# cyt2cl register map
Vendor: Cypress Semiconductor; Series: cyt2cl; File version: 1.0
CPU: CM4 r0p1, little endian, MPU, FPU, VTOR, 3 interrupt priority bits
Registers are 32-bit, read-write, reset 0x0 unless marked. A register's access mark holds for its fields unless they carry their own. Offsets are from the block's base; [hi:lo] are bit positions; lines under a group give offsets from that group; {n}, {i} and the like mark numbered series; 'fields as' and 'values as' point back to an identical list.

## GPIO — GPIO port control/configuration
Base 0x40310000
{0x0+0x80*i} PRT[{i}] (i=0..19) group — GPIO port registers
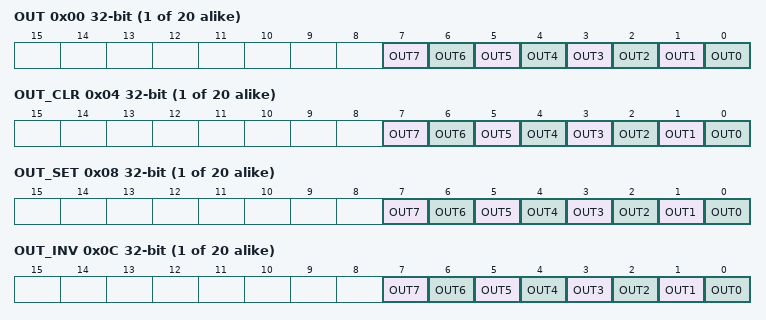
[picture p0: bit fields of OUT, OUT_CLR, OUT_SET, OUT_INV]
  0x00 OUT — Port output data register
    [n] OUT{n} (n=1..7) — IO output data for pin {n}
    [0] OUT0 — IO output data for pin 0 '0': Output state set to '0' '1': Output state set to '1'
  0x04 OUT_CLR — Port output data clear register
    [n] OUT{n} (n=1..7) — IO clear output for pin {n}
    [0] OUT0 — IO clear output for pin 0: '0': Output state not affected. '1': Output state set to '0'.
  0x08 OUT_SET — Port output data set register
    [n] OUT{n} (n=1..7) — IO set output for pin {n}
    [0] OUT0 — IO set output for pin 0: '0': Output state not affected. '1': Output state set to '1'.
  0x0C OUT_INV — Port output data invert register
    [n] OUT{n} (n=1..7) — IO invert output for pin {n}
    [0] OUT0 — IO invert output for pin 0: '0': Output state not affected. '1': Output state inverted ('0' => '1', '1' => '0').
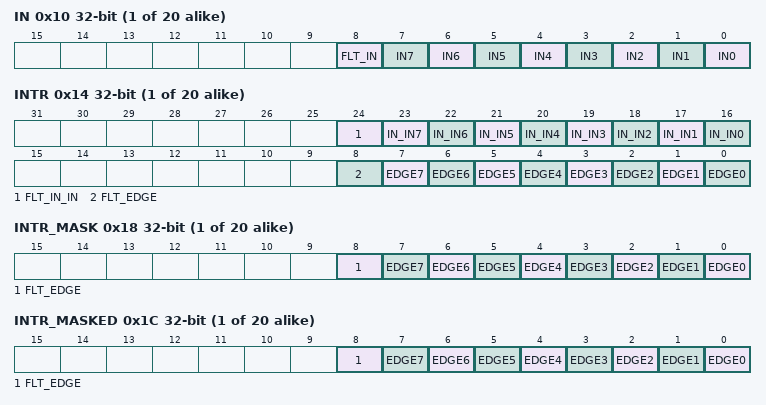
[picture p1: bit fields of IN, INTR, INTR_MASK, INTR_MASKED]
  0x10 IN ro — Port input state register
    [8] FLT_IN — Reads of this register return the logical state of the filtered pin as selected in the INTR_CFG.FLT_SEL register.
    [n] IN{n} (n=1..7) — IO pin state for pin {n}
    [0] IN0 — IO pin state for pin 0 '0': Low logic level present on pin. '1': High logic level present on pin. On reset assertion , IN register will get reset. The Pad value takes 2 clock cycles to be reflected into IN Register. It's value then depends on the external pin value.
  0x14 INTR — Port interrupt status register
    [24] FLT_IN_IN ro — Filtered pin state for pin selected by INTR_CFG.FLT_SEL
    [n+16] IN_IN{n} ro (n=0..7) — IO pin state for pin {n}
    [8] FLT_EDGE — Edge detected on filtered pin selected by INTR_CFG.FLT_SEL
    [n] EDGE{n} (n=1..7) — Edge detect for IO pin {n}
    [0] EDGE0 — Edge detect for IO pin 0 '0': No edge was detected on pin. '1': An edge was detected on pin.
  0x18 INTR_MASK — Port interrupt mask register
    [8] FLT_EDGE — Masks edge interrupt on filtered pin selected by INTR_CFG.FLT_SEL
    [n] EDGE{n} (n=1..7) — Masks edge interrupt on IO pin {n}
    [0] EDGE0 — Masks edge interrupt on IO pin 0 '0': Pin interrupt forwarding disabled '1': Pin interrupt forwarding enabled
  0x1C INTR_MASKED ro — Port interrupt masked status register
    [8] FLT_EDGE — Edge detected and masked on filtered pin selected by INTR_CFG.FLT_SEL
    [n] EDGE{n} (n=1..7) — Edge detected and masked on IO pin {n}
    [0] EDGE0 — Edge detected AND masked on IO pin 0 '0': Interrupt was not forwarded to CPU '1': Interrupt occurred and was forwarded to CPU
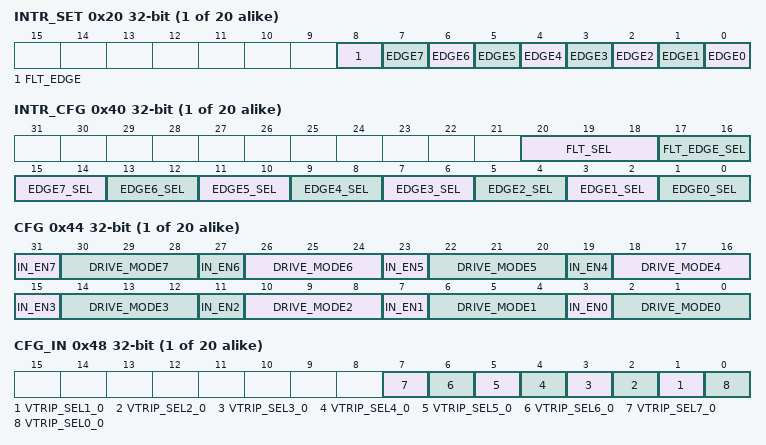
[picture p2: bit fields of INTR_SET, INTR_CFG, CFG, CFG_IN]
  0x20 INTR_SET — Port interrupt set register
    [8] FLT_EDGE — Sets edge detect interrupt for filtered pin selected by INTR_CFG.FLT_SEL
    [n] EDGE{n} (n=1..7) — Sets edge detect interrupt for IO pin {n}
    [0] EDGE0 — Sets edge detect interrupt for IO pin 0 '0': Interrupt state not affected '1': Interrupt set
  0x40 INTR_CFG — Port interrupt configuration register
    [20:18] FLT_SEL — Selects which pin is routed through the 50ns glitch filter to provide a glitch-safe interrupt.
    [17:16] FLT_EDGE_SEL — Sets which edge will trigger an IRQ for the glitch filtered pin (selected by INTR_CFG.FLT_SEL
      0=DISABLE (Disabled); 1=RISING (Rising edge); 2=FALLING (Falling edge); 3=BOTH (Both rising and falling edges)
    [2n+1:2n] EDGE{n}_SEL (n=1..7) — Sets which edge will trigger an IRQ for IO pin {n}
    [1:0] EDGE0_SEL — Sets which edge will trigger an IRQ for IO pin 0
      values as FLT_EDGE_SEL
  0x44 CFG — Port configuration register
    [4n+3] IN_EN{n} (n=1..7) — Enables the input buffer for IO pin {n}
    [30:28] DRIVE_MODE7 — The GPIO drive mode for IO pin 7
    [26:24] DRIVE_MODE6 — The GPIO drive mode for IO pin 6
    [22:20] DRIVE_MODE5 — The GPIO drive mode for IO pin 5
    [18:16] DRIVE_MODE4 — The GPIO drive mode for IO pin4
    [14:12] DRIVE_MODE3 — The GPIO drive mode for IO pin 3
    [10:8] DRIVE_MODE2 — The GPIO drive mode for IO pin 2
    [6:4] DRIVE_MODE1 — The GPIO drive mode for IO pin 1
    [3] IN_EN0 — Enables the input buffer for IO pin 0. This bit should be cleared when analog signals are present on the pin to avoid crowbar currents. The output buffer can be used to drive analog signals high or low without issue. '0': Input buffer disabled '1': Input buffer enabled
    [2:0] DRIVE_MODE0 — The GPIO drive mode for IO pin 0. Resistive pull-up and pull-down is selected in the drive mode. Note: when initializing IO's that are connected to a live bus (such as I2C), make sure the peripheral and HSIOM (HSIOM_PRT_SELx) is properly configured before turning the IO on here to avoid producing glitches on the bus. Note: that peripherals other than GPIO & UDB/DSI directly control both the output and output-enable of the output buffer (peripherals can drive strong 0 or strong 1 in any mode except OFF='0'). Note: D_OUT, D_OUT_EN are pins of GPIO cell.
      0=HIGHZ (Output buffer is off creating a high impedance input D_OUT = '0': High Impedance D_OUT = '1': High Impedance); 1=RSVD (N/A); 2=PULLUP (Resistive pull up For GPIO & UDB/DSI peripherals: When D_OUT_EN = 1: D_OUT = '0': Strong pull down D_OUT = '1': Weak/resistive pull up When D_OUT_EN = 0: D_OUT = '0': High impedance D_OUT = '1': High impedance For peripherals other than GPIO & UDB/DSI: When D_OUT_EN = 1: D_OUT = '0': Strong pull down D_OUT = '1': Strong pull up When D_OUT_EN = 0: D_OUT = '0': Weak/resistive pull up D_OUT = '1': Weak/resistive pull up); 3=PULLDOWN (Resistive pull down For GPIO & UDB/DSI peripherals: When D_OUT_EN = 1: D_OUT = '0': Weak/resistive pull down D_OUT = '1': Strong pull up When D_OUT_EN = 0: D_OUT = '0': High impedance D_OUT = '1': High impedance For peripherals other than GPIO & UDB/DSI: When D_OUT_EN = 1: D_OUT = '0': Strong pull down D_OUT = '1': Strong pull up When D_OUT_EN = 0: D_OUT = '0': Weak/resistive pull down D_OUT = '1': Weak/resistive pull down); 4=OD_DRIVESLOW (Open drain, drives low For GPIO & UDB/DSI peripherals: When D_OUT_EN = 1: D_OUT = '0': Strong pull down D_OUT = '1': High Impedance When D_OUT_EN = 0: D_OUT = '0': High impedance D_OUT = '1': High impedance For peripherals other than GPIO & UDB/DSI: When D_OUT_EN = 1: D_OUT = '0': Strong pull down D_OUT = '1': Strong pull up When D_OUT_EN = 0: D_OUT = '0': High Impedance D_OUT = '1': High Impedance); 5=OD_DRIVESHIGH (Open drain, drives high For GPIO & UDB/DSI peripherals: When D_OUT_EN = 1: D_OUT = '0': High Impedance D_OUT = '1': Strong pull up When D_OUT_EN = 0: D_OUT = '0': High impedance D_OUT = '1': High impedance For peripherals other than GPIO & UDB/DSI: When D_OUT_EN = 1: D_OUT = '0': Strong pull down D_OUT = '1': Strong pull up When D_OUT_EN = 0: D_OUT = '0': High Impedance D_OUT = '1': High Impedance); 6=STRONG (Strong D_OUTput buffer For GPIO & UDB/DSI peripherals: When D_OUT_EN = 1: D_OUT = '0': Strong pull down D_OUT = '1': Strong pull up When D_OUT_EN = 0: D_OUT = '0': High impedance D_OUT = '1': High impedance For peripherals other than GPIO & UDB/DSI: When D_OUT_EN = 1: D_OUT = '0': Strong pull down D_OUT = '1': Strong pull up When D_OUT_EN = 0: D_OUT = '0': High Impedance D_OUT = '1': High Impedance); 7=PULLUP_DOWN (Pull up or pull down For GPIO & UDB/DSI peripherals: When D_OUT_EN = '0': GPIO_DSI_OUT = '0': Weak/resistive pull down GPIO_DSI_OUT = '1': Weak/resistive pull up where 'GPIO_DSI_OUT' is a function of PORT_SEL, OUT & DSI_DATA_OUT. For peripherals other than GPIO & UDB/DSI: When D_OUT_EN = 1: D_OUT = '0': Strong pull down D_OUT = '1': Strong pull up When D_OUT_EN = 0: D_OUT = '0': Weak/resistive pull down D_OUT = '1': Weak/resistive pull up)
  0x48 CFG_IN — Port input buffer configuration register
    [n] VTRIP_SEL{n}_0 (n=1..7) — Configures the pin {n} input buffer mode (trip points and hysteresis)
    [0] VTRIP_SEL0_0 — Configures the pin 0 input buffer mode (trip points and hysteresis)
      0=CMOS (S40S: Input buffer compatible with CMOS and I2C interfaces S40E full encoding is shown in CFG_IN_AUTOLVL.VTRIP_SEL0_1); 1=TTL (S40S: Input buffer compatible with CMOS and I2C interfaces S40E full encoding is shown in CFG_IN_AUTOLVL.VTRIP_SEL0_1)
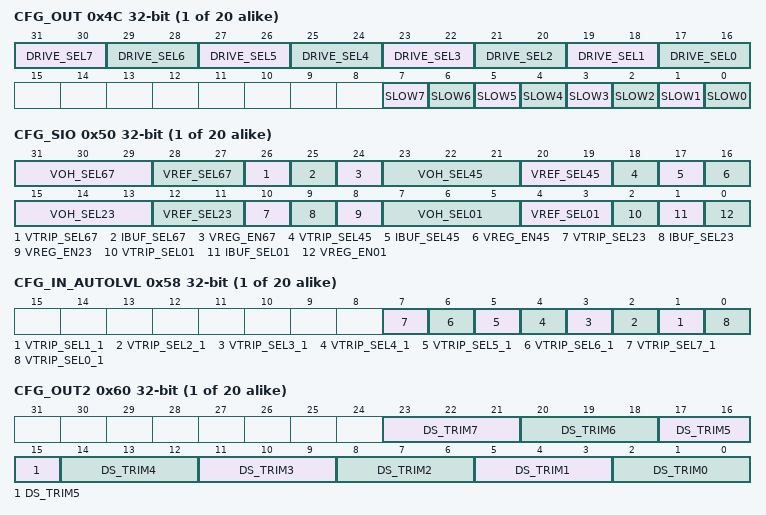
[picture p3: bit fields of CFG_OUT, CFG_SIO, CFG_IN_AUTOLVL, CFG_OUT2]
  0x4C CFG_OUT — Port output buffer configuration register
    [2n+17:2n+16] DRIVE_SEL{n} (n=1..7) — Sets the GPIO drive strength for IO pin {n}
    [17:16] DRIVE_SEL0 — Sets the GPIO drive strength for IO pin 0
      0=DRIVE_SEL_ZERO (Please refer to architecture TRM section I/O System); 1=DRIVE_SEL_ONE (Please refer to architecture TRM section I/O System); 2=DRIVE_SEL_TWO (Please refer to architecture TRM section I/O System); 3=DRIVE_SEL_THREE (Please refer to architecture TRM section I/O System)
    [n] SLOW{n} (n=1..7) — Enables slow slew rate for IO pin {n}
    [0] SLOW0 — Enables slow slew rate for IO pin 0 '0': Fast slew rate '1': Slow slew rate
  0x50 CFG_SIO — Port SIO configuration register
    [31:29] VOH_SEL67 — See corresponding definition for IO pins 0 and 1
    [28:27] VREF_SEL67 — See corresponding definition for IO pins 0 and 1
    [26] VTRIP_SEL67 — See corresponding definition for IO pins 0 and 1
    [25] IBUF_SEL67 — See corresponding definition for IO pins 0 and 1
    [24] VREG_EN67 — See corresponding definition for IO pins 0 and 1
    [23:21] VOH_SEL45 — See corresponding definition for IO pins 0 and 1
    [20:19] VREF_SEL45 — See corresponding definition for IO pins 0 and 1
    [18] VTRIP_SEL45 — See corresponding definition for IO pins 0 and 1
    [17] IBUF_SEL45 — See corresponding definition for IO pins 0 and 1
    [16] VREG_EN45 — See corresponding definition for IO pins 0 and 1
    [15:13] VOH_SEL23 — See corresponding definition for IO pins 0 and 1
    [12:11] VREF_SEL23 — See corresponding definition for IO pins 0 and 1
    [10] VTRIP_SEL23 — See corresponding definition for IO pins 0 and 1
    [9] IBUF_SEL23 — See corresponding definition for IO pins 0 and 1
    [8] VREG_EN23 — See corresponding definition for IO pins 0 and 1
    [7:5] VOH_SEL01 — Selects trip-point of input buffer. In single ended input buffer mode (IBUF01_SEL = '0'): 0: input buffer functions as a CMOS input buffer. 1: input buffer functions as a LVTTL input buffer. In differential input buffer mode (IBUF01_SEL = '1'): VTRIP_SEL=0: a) VREF_SEL=00, VOH_SEL=X -> Trip point=50 percent of vddio b) VREF_SEL=01, VOH_SEL=000 -> Trip point=Vohref (buffered) c) VREF_SEL=01, VOH_SEL=[1-7] -> Input buffer functions as CMOS input buffer. d) VREF_SEL=10/11, VOH_SEL=000 -> Trip point=Amuxbus_a/b (buffered) e) VREF_SEL=10/11, VOH_SEL=[1-7] -> Input buffer functions as CMOS input buffer. VTRIP_SEL=1: a) VREF_SEL=00, VOH_SEL=X -> Trip point=40 percent of vddio b) VREF_SEL=01, VOH_SEL=000 -> Trip point=0.5*Vohref c) VREF_SEL=01, VOH_SEL=[1-7] -> Input buffer functions as LVTTL input buffer. d) VREF_SEL=10/11, VOH_SEL=000 -> Trip point=0.5*Amuxbus_a/b (buffered) e) VREF_SEL=10/11, VOH_SEL=[1-7] -> Input buffer functions as LVTTL input buffer.
    [4:3] VREF_SEL01 — Selects reference voltage (Vref) trip-point of the input buffer: '0': Trip-point reference from pin_ref '1': Trip-point reference of SRSS internal reference Vref (1.2 V) '2': Trip-point reference of AMUXBUS_A '3': Trip-point reference of AMUXBUS_B
    [2] VTRIP_SEL01 — Selects the input buffer trip-point in single ended input buffer mode (IBUF_SEL = '0'): '0': Input buffer functions as a CMOS input buffer. '1': Input buffer functions as a TTL input buffer. In differential input buffer mode (IBUF_SEL = '1') '0': Trip-point is 0.5*Vddio or 0.5*Voh (depends on VREF_SEL/VOH_SEL) '1': Trip-point is 0.4*Vddio or 1.0*Vref (depends on VREF_SEL)
    [1] IBUF_SEL01 — Selects the input buffer mode: 0: Singled ended input buffer 1: Differential input buffer
    [0] VREG_EN01 — The regulated output mode is selected ONLY if the CFG.DRIVE_MODE bits are set to the strong pull up (Z_1 = '5') mode If the CFG.DRIVE_MODE bits are set to any other mode the regulated output buffer will be disabled and the standard CMOS output buffer is used.
  0x58 CFG_IN_AUTOLVL — Port input buffer AUTOLVL configuration register
    [n] VTRIP_SEL{n}_1 (n=1..7) — Input buffer compatible with automotive (elevated Vil) interfaces.
    [0] VTRIP_SEL0_1 — Configures the input buffer mode (trip points and hysteresis) for GPIO upper bit. Lower bit is still selected by CFG_IN.VTRIP_SEL0_0 field. This field is used along with CFG_IN.VTRIP_SEL0_0 field as below: {CFG_IN_AUTOLVL.VTRIP_SEL0_1,CFG_IN.VTRIP_SEL0_0}: 0,0: CMOS 0,1: TTL 1,0: input buffer is compatible with automotive. 1,1: input buffer is compatible with automotive. For GPIO OVT 1.2V variant, the encoding values of concatenation of CFG_IN_AUTOLVL.VTRIP_SEL0_1 and CFG_IN.VTRIP_SEL0_0 i.e. {CFG_IN_AUTOLVL.VTRIP_SEL0_1, CFG_IN.VTRIP_SEL0_0}are as below: 2'b00: CMOS 1.8V VIH/VIL = 65 percent/53 percent of VDDIO 2'b01: I2C 1.8V VIH/VIL = 70 percent/30 percent of VDDIO 2'b10: CMOS 1.2V VIH/VIL = 65 percent/35 percent of VDDIO 2'b11: I2C 1.2V VIH/VIL = 70 percent/30 percent of VDDIO
      0=CMOS_OR_TTL (Input buffer compatible with CMOS/TTL interfaces as described in CFG_IN.VTRIP_SEL0_0.); 1=AUTO (Input buffer compatible with AUTO (elevated Vil) interfaces when used along with CFG_IN.VTRIP_SEL0_0.)
  0x60 CFG_OUT2 — Port output buffer configuration register 2
    [3n+2:3n] DS_TRIM{n} (n=1..7) — Sets the Drive Select Trim for IO pin {n}
    [2:0] DS_TRIM0 — Sets the Drive Select Trim for IO pin 0 0 - Default (50ohms) 1 - 120ohms 2 - 90ohms 3 - 60ohms 4 - 50ohms 5 - 30ohms 6 - 20ohms 7 - 15ohms
      0=DEFAULT (N/A); 1=DS_120OHM (N/A); 2=DS_90OHM (N/A); 3=DS_60OHM (N/A); 4=DS_50OHM (N/A); 5=DS_30OHM (N/A); 6=DS_20OHM (N/A); 7=DS_15OHM (N/A)
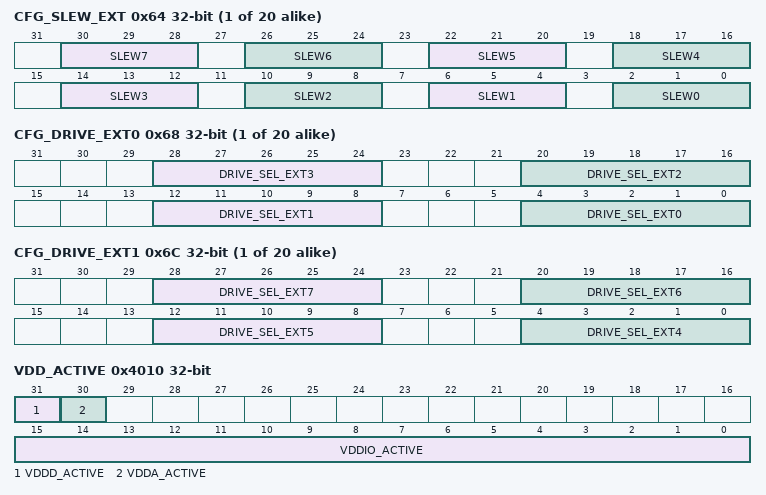
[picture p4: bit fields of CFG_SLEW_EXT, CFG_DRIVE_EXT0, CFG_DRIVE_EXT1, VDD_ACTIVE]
  0x64 CFG_SLEW_EXT — Port output buffer slew extension configuration register
    [4n+2:4n] SLEW{n} (n=1..7) — Slew rate for IO pin {n}
    [2:0] SLEW0 — Enables slow slew rate for IO pin 0 HSIO_STDLN: slew_ctl[SLEW_WIDTH] = All 0s: Fastest slew rate slew_ctl[SLEW_WIDTH] = All 1s: Slowest slew rate HSIO_ENH: slew_sel[SLEW_WIDTH] = All 0s: Fastest slew rate slew_sel[SLEW_WIDTH] = All 1s: Slowest slew rate
  0x68 CFG_DRIVE_EXT0 — Port output buffer drive sel extension configuration register
    [28:24] DRIVE_SEL_EXT3 — Sets the GPIO drive strength for IO pin 3
    [20:16] DRIVE_SEL_EXT2 — Sets the GPIO drive strength for IO pin 2
    [12:8] DRIVE_SEL_EXT1 — Sets the GPIO drive strength for IO pin 1
    [4:0] DRIVE_SEL_EXT0 — Sets the GPIO drive strength for IO pin 0. See description of CFG_OUT.DRIVE_SEL0 for options. For GPIO OVT 1.2V variant: Below are the encoding values: 3'b000 : 4mA drive strength, 1.8V 3'b001 : 3mA drive strength, 1.8V 3'b010 : 2mA drive strength, 1.8V 3'b011 : 1mA drive strength, 1.8V 3'b100 : 4mA drive strength, 1.2V 3'b101 : 3mA drive strength, 1.2V 3'b110 : 2mA drive strength, 1.2V 3'b111 : 1mA drive strength, 1.2V
  0x6C CFG_DRIVE_EXT1 — Port output buffer drive sel extension configuration register
    [28:24] DRIVE_SEL_EXT7 — Sets the GPIO drive strength for IO pin 7
    [20:16] DRIVE_SEL_EXT6 — Sets the GPIO drive strength for IO pin 6
    [12:8] DRIVE_SEL_EXT5 — Sets the GPIO drive strength for IO pin 5
    [4:0] DRIVE_SEL_EXT4 — Sets the GPIO drive strength for IO pin 4. See description of CFG_OUT.DRIVE_SEL0 for options. For GPIO OVT 1.2V variant only: Below are the encoding values: 3'b000 : 4mA drive strength, 1.8V 3'b001 : 3mA drive strength, 1.8V 3'b010 : 2mA drive strength, 1.8V 3'b011 : 1mA drive strength, 1.8V 3'b100 : 4mA drive strength, 1.2V 3'b101 : 3mA drive strength, 1.2V 3'b110 : 2mA drive strength, 1.2V 3'b111 : 1mA drive strength, 1.2V
0x4000 INTR_CAUSE0 ro — Interrupt port cause register 0
  [31:0] PORT_INT — Each IO port has an associated bit field in this register. The bit field reflects the IO port's interrupt line (bit field i reflects 'gpio_interrupts[i]' for IO port i). The register is used when the system uses a combined interrupt line 'gpio_interrupt'. The software ISR reads the register to determine which IO port(s) is responsible for the combined interrupt line. Once, the IO port(s) is determined, the IO port's GPIO_PRT_INTR register is read to determine the IO pin(s) in the IO port that caused the interrupt. '0': Port has no pending interrupt '1': Port has pending interrupt
{0x4000+4i} INTR_CAUSE{i} ro (i=1..3) — Interrupt port cause register {i}
  [31:0] PORT_INT — Each IO port has an associated bit field in this register. The bit field reflects the IO port's interrupt line (bit field i reflects 'gpio_interrupts[i]' for IO port i). The register is used when the system uses a combined interrupt line 'gpio_interrupt'. The software ISR reads the register to determine which IO port(s) is responsible for the combined interrupt line. Once, the IO port(s) is determined, the IO port's GPIO_PORT_INTR register is read to determine the IO pin(s) in the IO port that caused the interrupt. '0': Port has no pending interrupt '1': Port has pending interrupt
0x4010 VDD_ACTIVE ro — Extern power supply detection register
  [31] VDDD_ACTIVE — This bit indicates presence of the VDDD supply. This bit will always read-back 1. The VDDD supply has robust brown-out protection monitoring and it is not possible to read back this register without a valid supply. (This bit is used in certain test-modes to observe the brown-out detector status.)
  [30] VDDA_ACTIVE — Same as VDDIO_ACTIVE for the analog supply VDDA.
  [15:0] VDDIO_ACTIVE — Indicates presence or absence of VDDIO supplies (i.e. other than VDDD, VDDA) on the device (supplies are numbered 0..n-1). Note that VDDIO supplies have basic (crude) supply detectors only. If separate, robust, brown-out detection is desired on IO supplies, on-chip or off-chip analog resources need to provide it. For these bits to work reliable, the supply must be within valid spec range (per datasheet) or held at ground. Any in-between voltage has an undefined result. '0': Supply is not present '1': Supply is present When multiple VDDIO supplies are present, they will be assigned in alphanumeric ascending order to these bits during implementation. For example 'vddusb, vddio_0, vddio_a, vbackup, vddio_r, vddio_1' are present then they will be assigned to these bits as below: 0: vbackup, 1: vddio_0, 2: vddio_1, 3: vddio_a, 4: vddio_r, 5: vddusb'
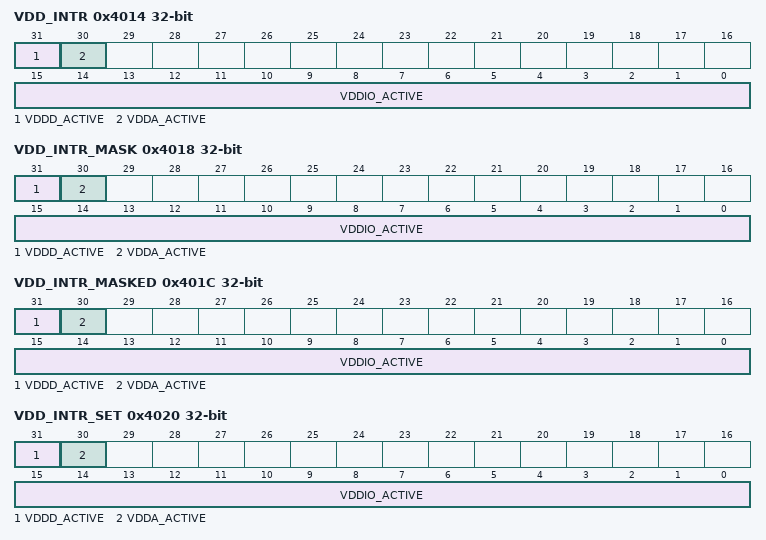
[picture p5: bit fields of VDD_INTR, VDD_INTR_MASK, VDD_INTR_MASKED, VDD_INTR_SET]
0x4014 VDD_INTR — Supply detection interrupt register
  [31] VDDD_ACTIVE — The VDDD supply is always present during operation so a supply transition can not occur. This bit will always read back '1'.
  [30] VDDA_ACTIVE — Same as VDDIO_ACTIVE for the analog supply VDDA.
  [15:0] VDDIO_ACTIVE — Supply state change detected. '0': No change to supply detected '1': Change to supply detected
0x4018 VDD_INTR_MASK — Supply detection interrupt mask register
  [31] VDDD_ACTIVE — Same as VDDIO_ACTIVE for the digital supply VDDD.
  [30] VDDA_ACTIVE — Same as VDDIO_ACTIVE for the analog supply VDDA.
  [15:0] VDDIO_ACTIVE — Masks supply interrupt on VDDIO. '0': VDDIO interrupt forwarding disabled '1': VDDIO interrupt forwarding enabled
0x401C VDD_INTR_MASKED ro — Supply detection interrupt masked register
  [31] VDDD_ACTIVE — Same as VDDIO_ACTIVE for the digital supply VDDD.
  [30] VDDA_ACTIVE — Same as VDDIO_ACTIVE for the analog supply VDDA.
  [15:0] VDDIO_ACTIVE — Supply transition detected AND masked '0': Interrupt was not forwarded to CPU '1': Interrupt occurred and was forwarded to CPU
0x4020 VDD_INTR_SET — Supply detection interrupt set register
  [31] VDDD_ACTIVE — Same as VDDIO_ACTIVE for the digital supply VDDD.
  [30] VDDA_ACTIVE — Same as VDDIO_ACTIVE for the analog supply VDDA.
  [15:0] VDDIO_ACTIVE — Sets supply interrupt. '0': Interrupt state not affected '1': Interrupt set
0x4024 VDD_LVL ro — External power supply level register
  [15:0] VDDIO_LVL — The VDD_LVL circuit detects the VDDIO supply level and writes the detected value in this register. '0' indicates the VDDIO supply is at 1.2V and '1' indicates VDDIO supply is at 1.8V.
